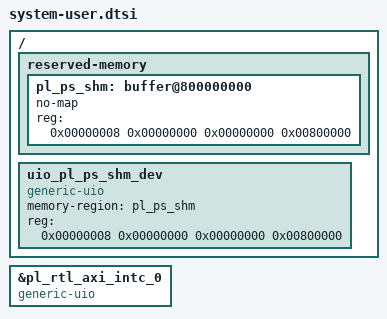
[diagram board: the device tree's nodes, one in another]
/include/ "system-conf.dtsi"
/ {
};

&pl_rtl_axi_intc_0 {
  compatible = "generic-uio";
};



/ {
  reserved-memory {
    #address-cells = <2>; // or <1> for 32-bit
    #size-cells = <2>;    // or <1> for 32-bit
    ranges;

    // Define the reserved region
    pl_ps_shm: buffer@800000000 {
        no-map;
        /* Base High: 0x8, Base Low: 0x0 | Size High: 0x0, Size Low: 0x800000 (8MB) */
        reg = <0x00000008 0x00000000 0x00000000 0x00800000>;
    };
  };

/* The UIO device that points to it */
    uio_pl_ps_shm_dev {
        compatible = "generic-uio";
        memory-region = <&pl_ps_shm>;
        reg = <0x00000008 0x00000000 0x00000000 0x00800000>;
    };
};
